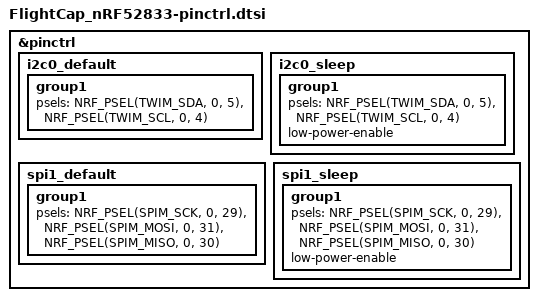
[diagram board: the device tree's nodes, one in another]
&pinctrl {
	i2c0_default: i2c0_default {
		group1 {
			psels = <NRF_PSEL(TWIM_SDA, 0, 5)>,
				<NRF_PSEL(TWIM_SCL, 0, 4)>;
		};
	};

	i2c0_sleep: i2c0_sleep {
		group1 {
			psels = <NRF_PSEL(TWIM_SDA, 0, 5)>,
				<NRF_PSEL(TWIM_SCL, 0, 4)>;
			low-power-enable;
		};
	};

	spi1_default: spi1_default {
		group1 {
			psels = <NRF_PSEL(SPIM_SCK, 0, 29)>,
				<NRF_PSEL(SPIM_MOSI, 0, 31)>,
				<NRF_PSEL(SPIM_MISO, 0, 30)>;
		};
	};

	spi1_sleep: spi1_sleep {
		group1 {
			psels = <NRF_PSEL(SPIM_SCK, 0, 29)>,
				<NRF_PSEL(SPIM_MOSI, 0, 31)>,
				<NRF_PSEL(SPIM_MISO, 0, 30)>;
			low-power-enable;
		};
	};
};
